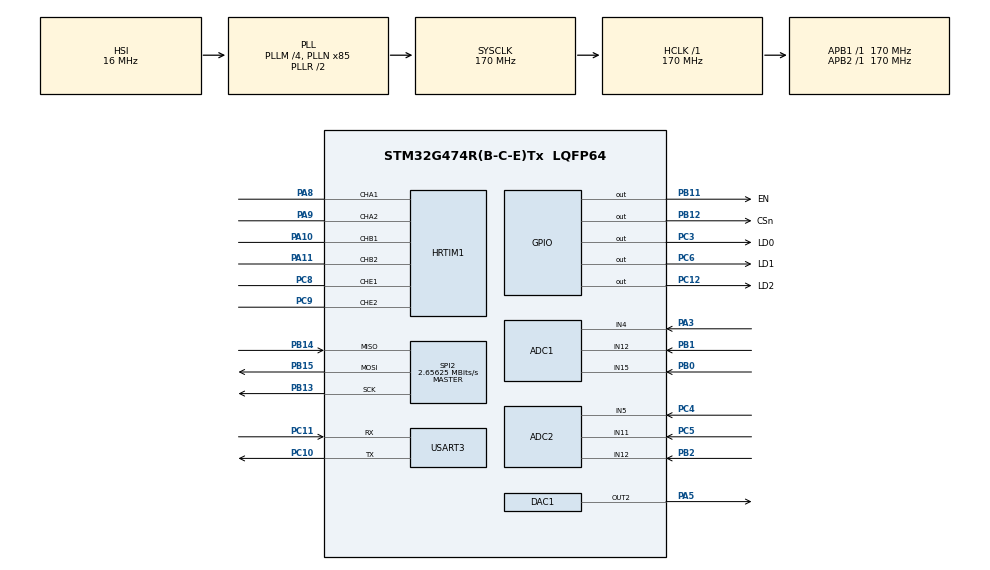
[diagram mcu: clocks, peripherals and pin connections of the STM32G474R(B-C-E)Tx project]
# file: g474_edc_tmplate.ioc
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ADC1.Channel-3\#ChannelRegularConversion=ADC_CHANNEL_15
ADC1.Channel-6\#ChannelRegularConversion=ADC_CHANNEL_4
ADC1.DMAAccessModeView=ENABLE
ADC1.DMAContinuousRequests=ENABLE
ADC1.ExternalTrigConv=ADC_EXTERNALTRIG_HRTIM_TRG1
ADC1.Mode=ADC_DUALMODE_REGSIMULT
ADC1.NbrOfConversion=2
ADC1.NbrOfConversionFlag=1
ADC1.OffsetNumber-3\#ChannelRegularConversion=ADC_OFFSET_NONE
ADC1.OffsetNumber-6\#ChannelRegularConversion=ADC_OFFSET_NONE
ADC1.Rank-3\#ChannelRegularConversion=1
ADC1.Rank-6\#ChannelRegularConversion=2
ADC1.SamplingTime-3\#ChannelRegularConversion=ADC_SAMPLETIME_12CYCLES_5
ADC1.SamplingTime-6\#ChannelRegularConversion=ADC_SAMPLETIME_12CYCLES_5
ADC1.master=1
ADC2.Channel-3\#ChannelRegularConversion=ADC_CHANNEL_12
ADC2.Channel-6\#ChannelRegularConversion=ADC_CHANNEL_12
ADC2.DMAAccessModeView=ENABLE
ADC2.Mode=ADC_DUALMODE_REGSIMULT
ADC2.NbrOfConversion=2
ADC2.NbrOfConversionFlag=1
ADC2.OffsetNumber-3\#ChannelRegularConversion=ADC_OFFSET_NONE
ADC2.OffsetNumber-6\#ChannelRegularConversion=ADC_OFFSET_NONE
ADC2.Rank-3\#ChannelRegularConversion=1
ADC2.Rank-6\#ChannelRegularConversion=2
ADC2.SamplingTime-3\#ChannelRegularConversion=ADC_SAMPLETIME_12CYCLES_5
ADC2.SamplingTime-6\#ChannelRegularConversion=ADC_SAMPLETIME_12CYCLES_5
DAC1.DAC_Channel-DAC_OUT2=DAC_CHANNEL_2
Dma.ADC1.0.Direction=DMA_PERIPH_TO_MEMORY
Dma.ADC1.0.EventEnable=DISABLE
Dma.ADC1.0.Instance=DMA1_Channel1
Dma.ADC1.0.MemDataAlignment=DMA_MDATAALIGN_WORD
Dma.ADC1.0.MemInc=DMA_MINC_ENABLE
Dma.ADC1.0.Mode=DMA_CIRCULAR
Dma.ADC1.0.PeriphDataAlignment=DMA_PDATAALIGN_WORD
Dma.ADC1.0.PeriphInc=DMA_PINC_DISABLE
Dma.ADC1.0.Polarity=HAL_DMAMUX_REQ_GEN_RISING
Dma.ADC1.0.Priority=DMA_PRIORITY_LOW
Dma.ADC1.0.RequestNumber=1
Dma.ADC1.0.SignalID=NONE
Dma.ADC1.0.SyncEnable=DISABLE
Dma.ADC1.0.SyncPolarity=HAL_DMAMUX_SYNC_NO_EVENT
Dma.ADC1.0.SyncRequestNumber=1
Dma.ADC1.0.SyncSignalID=NONE
Dma.Request0=ADC1
Dma.Request1=USART3_TX
Dma.Request2=USART3_RX
Dma.USART3_RX.2.Direction=DMA_PERIPH_TO_MEMORY
Dma.USART3_RX.2.EventEnable=DISABLE
Dma.USART3_RX.2.Instance=DMA1_Channel3
Dma.USART3_RX.2.MemDataAlignment=DMA_MDATAALIGN_BYTE
Dma.USART3_RX.2.MemInc=DMA_MINC_ENABLE
Dma.USART3_RX.2.Mode=DMA_NORMAL
Dma.USART3_RX.2.PeriphDataAlignment=DMA_PDATAALIGN_BYTE
Dma.USART3_RX.2.PeriphInc=DMA_PINC_DISABLE
Dma.USART3_RX.2.Polarity=HAL_DMAMUX_REQ_GEN_RISING
Dma.USART3_RX.2.Priority=DMA_PRIORITY_LOW
Dma.USART3_RX.2.RequestNumber=1
Dma.USART3_RX.2.SignalID=NONE
Dma.USART3_RX.2.SyncEnable=DISABLE
Dma.USART3_RX.2.SyncPolarity=HAL_DMAMUX_SYNC_NO_EVENT
Dma.USART3_RX.2.SyncRequestNumber=1
Dma.USART3_RX.2.SyncSignalID=NONE
Dma.USART3_TX.1.Direction=DMA_MEMORY_TO_PERIPH
Dma.USART3_TX.1.EventEnable=DISABLE
Dma.USART3_TX.1.Instance=DMA1_Channel2
Dma.USART3_TX.1.MemDataAlignment=DMA_MDATAALIGN_BYTE
Dma.USART3_TX.1.MemInc=DMA_MINC_ENABLE
Dma.USART3_TX.1.Mode=DMA_NORMAL
Dma.USART3_TX.1.PeriphDataAlignment=DMA_PDATAALIGN_BYTE
Dma.USART3_TX.1.PeriphInc=DMA_PINC_DISABLE
Dma.USART3_TX.1.Polarity=HAL_DMAMUX_REQ_GEN_RISING
Dma.USART3_TX.1.Priority=DMA_PRIORITY_LOW
Dma.USART3_TX.1.RequestNumber=1
Dma.USART3_TX.1.SignalID=NONE
Dma.USART3_TX.1.SyncEnable=DISABLE
Dma.USART3_TX.1.SyncPolarity=HAL_DMAMUX_SYNC_NO_EVENT
Dma.USART3_TX.1.SyncRequestNumber=1
Dma.USART3_TX.1.SyncSignalID=NONE
HRTIM1.ADCTrigger1_Source1=HRTIM_ADCTRIGGEREVENT13_MASTER_CMP1
HRTIM1.ADCTrigger_Id1=HRTIM_ADCTRIGGER_1
HRTIM1.CompareUnit1-MasterTimer=HRTIM_COMPAREUNIT_1
HRTIM1.CompareUnit1-Output_TA1TA2=HRTIM_COMPAREUNIT_1
HRTIM1.CompareUnit1-Output_TB1TB2=HRTIM_COMPAREUNIT_1
HRTIM1.CompareUnit1-Output_TE1TE2=HRTIM_COMPAREUNIT_1
HRTIM1.CompareUnit2-Output_TA1TA2=HRTIM_COMPAREUNIT_2
HRTIM1.CompareUnit2-Output_TB1TB2=HRTIM_COMPAREUNIT_2
HRTIM1.CompareUnit2-Output_TE1TE2=HRTIM_COMPAREUNIT_2
HRTIM1.CompareUnit3-Output_TA1TA2=__NULL
HRTIM1.CompareUnit4-Output_TA1TA2=__NULL
HRTIM1.CompareValue1-MasterTimer=30000
HRTIM1.CompareValue1-Output_TA1TA2=20000
HRTIM1.CompareValue1-Output_TB1TB2=10000
HRTIM1.CompareValue1-Output_TE1TE2=25000
HRTIM1.CompareValue2-Output_TA1TA2=40000
HRTIM1.CompareValue2-Output_TB1TB2=50000
HRTIM1.CompareValue2-Output_TE1TE2=35000
HRTIM1.DeadTimeInsertion-Output_TA1TA2=HRTIM_TIMDEADTIMEINSERTION_ENABLED
HRTIM1.DeadTimeInsertion-Output_TB1TB2=HRTIM_TIMDEADTIMEINSERTION_ENABLED
HRTIM1.DeadTimeInsertion-Output_TE1TE2=HRTIM_TIMDEADTIMEINSERTION_ENABLED
HRTIM1.Deadtimeconfig-Output_TA1TA2=HRTIM_TIMERINDEX_TIMER_A
HRTIM1.Deadtimeconfig-Output_TB1TB2=HRTIM_TIMERINDEX_TIMER_B
HRTIM1.FallingValue-Output_TA1TA2=200
HRTIM1.FallingValue-Output_TB1TB2=200
HRTIM1.FallingValue-Output_TE1TE2=200
HRTIM1.GreaterCMP1_TA=HRTIM_TIMERGTCMP1_EQUAL
HRTIM1.NumberADCTriggerSource1=1
HRTIM1.NumberResetSource1-Output_TA1TA2=1
HRTIM1.NumberResetSource1-Output_TB1TB2=1
HRTIM1.NumberResetSource1-Output_TE1TE2=1
HRTIM1.NumberResetTrigger-Output_TA1TA2=1
HRTIM1.NumberResetTrigger-Output_TB1TB2=1
HRTIM1.NumberResetTrigger-Output_TE1TE2=1
HRTIM1.NumberSetSource1-Output_TA1TA2=1
HRTIM1.NumberSetSource1-Output_TB1TB2=1
HRTIM1.NumberSetSource1-Output_TE1TE2=1
HRTIM1.NumberSetSource2_TA=0
HRTIM1.Periode_MASTER=40000
HRTIM1.Periode_TA=40000
HRTIM1.Periode_TB=40000
HRTIM1.Periode_TE=40000
HRTIM1.PrescalerRatio_MASTER=HRTIM_PRESCALERRATIO_MUL8
HRTIM1.PrescalerRatio_TA=HRTIM_PRESCALERRATIO_MUL8
HRTIM1.PrescalerRatio_TB=HRTIM_PRESCALERRATIO_MUL8
HRTIM1.PrescalerRatio_TE=HRTIM_PRESCALERRATIO_MUL8
HRTIM1.ResetOutput1_Source1-Output_TA1TA2=HRTIM_OUTPUTRESET_TIMCMP2
HRTIM1.ResetOutput1_Source1-Output_TB1TB2=HRTIM_OUTPUTRESET_TIMCMP2
HRTIM1.ResetOutput1_Source1-Output_TE1TE2=HRTIM_OUTPUTRESET_TIMCMP2
HRTIM1.ResetTrigger1-Output_TA1TA2=HRTIM_TIMRESETTRIGGER_MASTER_PER
HRTIM1.ResetTrigger1-Output_TB1TB2=HRTIM_TIMRESETTRIGGER_MASTER_PER
HRTIM1.ResetTrigger1-Output_TE1TE2=HRTIM_TIMRESETTRIGGER_MASTER_PER
HRTIM1.RisingValue-Output_TA1TA2=200
HRTIM1.RisingValue-Output_TB1TB2=200
HRTIM1.RisingValue-Output_TE1TE2=200
HRTIM1.SetOutput1_Source1-Output_TA1TA2=HRTIM_OUTPUTSET_TIMCMP1
HRTIM1.SetOutput1_Source1-Output_TB1TB2=HRTIM_OUTPUTSET_TIMCMP1
HRTIM1.SetOutput1_Source1-Output_TE1TE2=HRTIM_OUTPUTSET_TIMCMP1
HRTIM1.SyncOptions=HRTIM_SYNCOPTION_NONE
Mcu.Family=STM32G4
Mcu.Name=STM32G474R(B-C-E)Tx
Mcu.Package=LQFP64
NVIC.ADC1_2_IRQn=true\:0\:0\:false\:false\:true\:true\:true\:true
NVIC.DMA1_Channel1_IRQn=true\:0\:0\:false\:false\:true\:false\:true\:true
NVIC.DMA1_Channel2_IRQn=true\:0\:0\:false\:false\:true\:false\:true\:true
NVIC.DMA1_Channel3_IRQn=true\:0\:0\:false\:false\:true\:false\:true\:true
NVIC.PriorityGroup=NVIC_PRIORITYGROUP_4
NVIC.SPI2_IRQn=true\:0\:0\:false\:false\:true\:true\:true\:true
NVIC.TIM6_DAC_IRQn=true\:1\:0\:true\:false\:true\:true\:true\:true
NVIC.TIM7_DAC_IRQn=true\:0\:0\:false\:false\:true\:true\:true\:true
NVIC.USART3_IRQn=true\:0\:0\:false\:false\:true\:true\:true\:true
PA10.Mode=Output_TB1TB2
PA10.Signal=HRTIM1_CHB1
PA11.Mode=Output_TB1TB2
PA11.Signal=HRTIM1_CHB2
PA13.Mode=Serial_Wire
PA13.Signal=SYS_JTMS-SWDIO
PA14.Mode=Serial_Wire
PA14.Signal=SYS_JTCK-SWCLK
PA3.Mode=IN4-Single-Ended
PA3.Signal=ADC1_IN4
PA5.Signal=COMP_DAC12_group
PA8.Mode=Output_TA1TA2
PA8.Signal=HRTIM1_CHA1
PA9.Mode=Output_TA1TA2
PA9.Signal=HRTIM1_CHA2
PB0.Mode=IN15-Single-Ended
PB0.Signal=ADC1_IN15
PB1.Mode=IN12-Single-Ended
PB1.Signal=ADC1_IN12
PB11.GPIO_Label=EN
PB11.Signal=GPIO_Output
PB12.GPIO_Label=CSn
PB12.PinState=GPIO_PIN_SET
PB12.Signal=GPIO_Output
PB13.Mode=Full_Duplex_Master
PB13.Signal=SPI2_SCK
PB14.Mode=Full_Duplex_Master
PB14.Signal=SPI2_MISO
PB15.Mode=Full_Duplex_Master
PB15.Signal=SPI2_MOSI
PB2.Mode=IN12-Single-Ended
PB2.Signal=ADC2_IN12
PC10.Mode=Asynchronous
PC10.Signal=USART3_TX
PC11.Mode=Asynchronous
PC11.Signal=USART3_RX
PC12.GPIO_Label=LD2
PC12.Signal=GPIO_Output
PC3.GPIO_Label=LD0
PC3.Signal=GPIO_Output
PC4.Mode=IN5-Single-Ended
PC4.Signal=ADC2_IN5
PC5.Mode=IN11-Single-Ended
PC5.Signal=ADC2_IN11
PC6.GPIO_Label=LD1
PC6.Signal=GPIO_Output
PC8.Mode=Output_TE1TE2
PC8.Signal=HRTIM1_CHE1
PC9.Mode=Output_TE1TE2
PC9.Signal=HRTIM1_CHE2
PF0-OSC_IN.Mode=HSE-External-Oscillator
PF0-OSC_IN.Signal=RCC_OSC_IN
PF1-OSC_OUT.Mode=HSE-External-Oscillator
PF1-OSC_OUT.Signal=RCC_OSC_OUT
ProjectManager.HeapSize=0x200
ProjectManager.StackSize=0x400
ProjectManager.TargetToolchain=CMake
RCC.ADC12Freq_Value=170000000
RCC.ADC345Freq_Value=170000000
RCC.AHBFreq_Value=170000000
RCC.APB1Freq_Value=170000000
RCC.APB1TimFreq_Value=170000000
RCC.APB2Freq_Value=170000000
RCC.APB2TimFreq_Value=170000000
RCC.CortexFreq_Value=170000000
RCC.EXTERNAL_CLOCK_VALUE=12288000
RCC.HCLKFreq_Value=170000000
RCC.HSE_VALUE=27000000
RCC.HSI48_VALUE=48000000
RCC.HSI_VALUE=16000000
RCC.LSE_VALUE=32768
RCC.PLLM=RCC_PLLM_DIV4
RCC.PLLN=85
RCC.SYSCLKFreq_VALUE=170000000
RCC.SYSCLKSource=RCC_SYSCLKSOURCE_PLLCLK
RCC.USBFreq_Value=170000000
RCC.VCOOutputFreq_Value=340000000
SH.COMP_DAC12_group.0=DAC1_OUT2,DAC_OUT2
SPI2.BaudRatePrescaler=SPI_BAUDRATEPRESCALER_64
SPI2.CLKPhase=SPI_PHASE_2EDGE
SPI2.CLKPolarity=SPI_POLARITY_HIGH
SPI2.CalculateBaudRate=2.65625 MBits/s
SPI2.DataSize=SPI_DATASIZE_8BIT
SPI2.Direction=SPI_DIRECTION_2LINES
SPI2.Mode=SPI_MODE_MASTER
SPI2.VirtualType=VM_MASTER
STMicroelectronics.X-CUBE-ALGOBUILD.1.3.0.LibraryCcDSPOoLibraryJjDSPOoLibrary=true
TIM6.PeriodNoDither=100
TIM6.Prescaler=169
TIM7.PeriodNoDither=10000
TIM7.Prescaler=169
USART3.VirtualMode-Asynchronous=VM_ASYNC
VP_HRTIM1_VS_hrtimMasterTimerNoOutput.Mode=MasterTimer
VP_STMicroelectronics.X-CUBE-ALGOBUILD_VS_DSPOoLibraryJjLibrary_1.3.0_1.3.0.Mode=DSPOoLibraryJjLibrary
VP_SYS_VS_DBSignals.Mode=DisableDeadBatterySignals
VP_TIM6_VS_ClockSourceINT.Mode=Enable_Timer
VP_TIM7_VS_ClockSourceINT.Mode=Enable_Timer
board=custom

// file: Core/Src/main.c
/* USER CODE BEGIN Header */
/**
  ******************************************************************************
  * @file           : main.c
  * @brief          : Main program body
  ******************************************************************************
  * @attention
  *
  * Copyright (c) 2026 STMicroelectronics.
  * All rights reserved.
  *
  * This software is licensed under terms that can be found in the LICENSE file
  * in the root directory of this software component.
  * If no LICENSE file comes with this software, it is provided AS-IS.
  *
  ******************************************************************************
  */
/* USER CODE END Header */
#include "main.h"
#include "adc.h"
#include "dac.h"
#include "dma.h"
#include "hrtim.h"
#include "spi.h"
#include "tim.h"
#include "usart.h"
#include "gpio.h"

/* USER CODE BEGIN Includes */
#include "Entry.h"
/* USER CODE END Includes */

void SystemClock_Config(void);

int main(void)
{

  /* MCU Configuration--------------------------------------------------------*/

  /* Reset of all peripherals, Initializes the Flash interface and the Systick. */
  HAL_Init();

  /* Configure the system clock */
  SystemClock_Config();

  /* Initialize all configured peripherals */
  MX_GPIO_Init();
  MX_DMA_Init();
  MX_HRTIM1_Init();
  MX_TIM6_Init();
  MX_ADC1_Init();
  MX_ADC2_Init();
  MX_USART3_UART_Init();
  MX_TIM7_Init();
  MX_SPI2_Init();
  MX_DAC1_Init();
  /* USER CODE BEGIN 2 */
  Entry();
  /* USER CODE END 2 */

  /* Infinite loop */
  while (1)
  {

  }
}

void SystemClock_Config(void)
{
  RCC_OscInitTypeDef RCC_OscInitStruct = {0};
  RCC_ClkInitTypeDef RCC_ClkInitStruct = {0};

  /** Configure the main internal regulator output voltage
  */
  HAL_PWREx_ControlVoltageScaling(PWR_REGULATOR_VOLTAGE_SCALE1_BOOST);

  /** Initializes the RCC Oscillators according to the specified parameters
  * in the RCC_OscInitTypeDef structure.
  */
  RCC_OscInitStruct.OscillatorType = RCC_OSCILLATORTYPE_HSI;
  RCC_OscInitStruct.HSIState = RCC_HSI_ON;
  RCC_OscInitStruct.HSICalibrationValue = RCC_HSICALIBRATION_DEFAULT;
  RCC_OscInitStruct.PLL.PLLState = RCC_PLL_ON;
  RCC_OscInitStruct.PLL.PLLSource = RCC_PLLSOURCE_HSI;
  RCC_OscInitStruct.PLL.PLLM = RCC_PLLM_DIV4;
  RCC_OscInitStruct.PLL.PLLN = 85;
  RCC_OscInitStruct.PLL.PLLP = RCC_PLLP_DIV2;
  RCC_OscInitStruct.PLL.PLLQ = RCC_PLLQ_DIV2;
  RCC_OscInitStruct.PLL.PLLR = RCC_PLLR_DIV2;
  if (HAL_RCC_OscConfig(&RCC_OscInitStruct) != HAL_OK)
  {
    Error_Handler();
  }

  /** Initializes the CPU, AHB and APB buses clocks
  */
  RCC_ClkInitStruct.ClockType = RCC_CLOCKTYPE_HCLK|RCC_CLOCKTYPE_SYSCLK
                              |RCC_CLOCKTYPE_PCLK1|RCC_CLOCKTYPE_PCLK2;
  RCC_ClkInitStruct.SYSCLKSource = RCC_SYSCLKSOURCE_PLLCLK;
  RCC_ClkInitStruct.AHBCLKDivider = RCC_SYSCLK_DIV1;
  RCC_ClkInitStruct.APB1CLKDivider = RCC_HCLK_DIV1;
  RCC_ClkInitStruct.APB2CLKDivider = RCC_HCLK_DIV1;

  if (HAL_RCC_ClockConfig(&RCC_ClkInitStruct, FLASH_LATENCY_4) != HAL_OK)
  {
    Error_Handler();
  }
}

void Error_Handler(void)
{
  __disable_irq();
  while (1)
  {
  }
}
